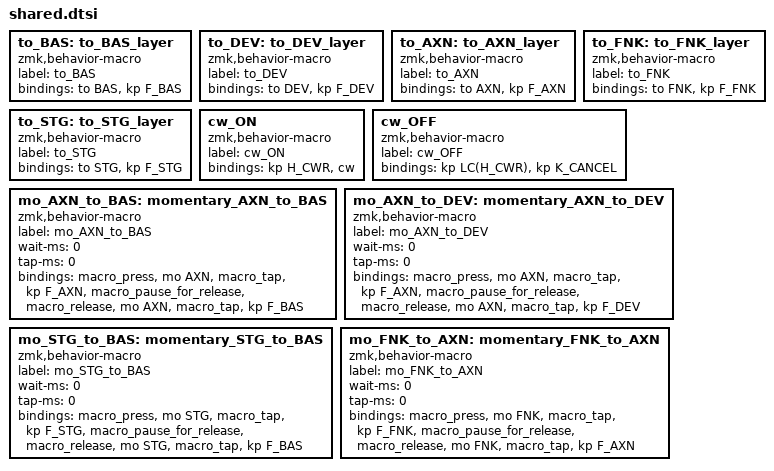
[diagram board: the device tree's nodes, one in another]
to_BAS: to_BAS_layer {
    compatible = "zmk,behavior-macro";
    label = "to_BAS";
    #binding-cells = <0>;
    bindings =
        <&to BAS &kp F_BAS>;
};

to_DEV: to_DEV_layer {
    compatible = "zmk,behavior-macro";
    label = "to_DEV";
    #binding-cells = <0>;
    bindings =
        <&to DEV &kp F_DEV>;
};

to_AXN: to_AXN_layer {
    compatible = "zmk,behavior-macro";
    label = "to_AXN";
    #binding-cells = <0>;
    bindings =
        <&to AXN &kp F_AXN>;
};

to_FNK: to_FNK_layer {
    compatible = "zmk,behavior-macro";
    label = "to_FNK";
    #binding-cells = <0>;
    bindings =
        <&to FNK &kp F_FNK>;
};

to_STG: to_STG_layer {
    compatible = "zmk,behavior-macro";
    label = "to_STG";
    #binding-cells = <0>;
    bindings =
        <&to STG &kp F_STG>;
};

cw_ON: cw_ON {
    compatible = "zmk,behavior-macro";
    label = "cw_ON";
    #binding-cells = <0>;
    bindings =
        <&kp H_CWR &cw>;
};

cw_OFF: cw_OFF {
    compatible = "zmk,behavior-macro";
    label = "cw_OFF";
    #binding-cells = <0>;
    bindings =
        <&kp LC(H_CWR) &kp K_CANCEL>;
};

mo_AXN_to_BAS: momentary_AXN_to_BAS {
    compatible = "zmk,behavior-macro";
    label = "mo_AXN_to_BAS";
    #binding-cells = <0>;
    wait-ms = <0>;
    tap-ms = <0>;
    bindings
        = <&macro_press &mo AXN>
        , <&macro_tap &kp F_AXN>
        , <&macro_pause_for_release>
        , <&macro_release &mo AXN>
        , <&macro_tap &kp F_BAS>;
};

mo_AXN_to_DEV: momentary_AXN_to_DEV {
    compatible = "zmk,behavior-macro";
    label = "mo_AXN_to_DEV";
    #binding-cells = <0>;
    wait-ms = <0>;
    tap-ms = <0>;
    bindings
        = <&macro_press &mo AXN>
        , <&macro_tap &kp F_AXN>
        , <&macro_pause_for_release>
        , <&macro_release &mo AXN>
        , <&macro_tap &kp F_DEV>;
};

mo_STG_to_BAS: momentary_STG_to_BAS {
    compatible = "zmk,behavior-macro";
    label = "mo_STG_to_BAS";
    #binding-cells = <0>;
    wait-ms = <0>;
    tap-ms = <0>;
    bindings
        = <&macro_press &mo STG>
        , <&macro_tap &kp F_STG>
        , <&macro_pause_for_release>
        , <&macro_release &mo STG>
        , <&macro_tap &kp F_BAS>;
};

mo_FNK_to_AXN: momentary_FNK_to_AXN {
    compatible = "zmk,behavior-macro";
    label = "mo_FNK_to_AXN";
    #binding-cells = <0>;
    wait-ms = <0>;
    tap-ms = <0>;
    bindings
        = <&macro_press &mo FNK>
        , <&macro_tap &kp F_FNK>
        , <&macro_pause_for_release>
        , <&macro_release &mo FNK>
        , <&macro_tap &kp F_AXN>;
};
